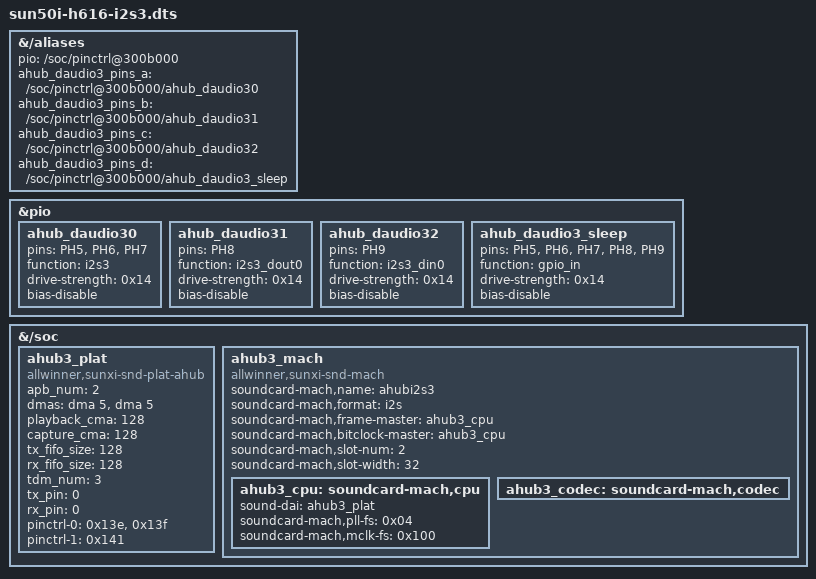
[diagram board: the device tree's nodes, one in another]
/dts-v1/;
/plugin/;

&{/aliases} {
	pio = "/soc/pinctrl@300b000";
	ahub_daudio3_pins_a = "/soc/pinctrl@300b000/ahub_daudio30";
	ahub_daudio3_pins_b = "/soc/pinctrl@300b000/ahub_daudio31";
	ahub_daudio3_pins_c = "/soc/pinctrl@300b000/ahub_daudio32";
	ahub_daudio3_pins_d = "/soc/pinctrl@300b000/ahub_daudio3_sleep";
	};

&pio {
		ahub_daudio30 {
			pins = "PH5", "PH6", "PH7";
			function = "i2s3";
			drive-strength = <0x14>;
			bias-disable;
			phandle = <0xa0>;
						};
		ahub_daudio31 {
			pins = "PH8";
			function = "i2s3_dout0";
			drive-strength = <0x14>;
			bias-disable;
			phandle = <0xa1>;
						};
		ahub_daudio32  {
			pins = "PH9";
			function = "i2s3_din0";
			drive-strength = <0x14>;
			bias-disable;
			phandle = <0xa2>;
						};
		ahub_daudio3_sleep  {
			pins = "PH5", "PH6", "PH7", "PH8", "PH9";
			function = "gpio_in";
			drive-strength = <0x14>;
			bias-disable;
			phandle = <0xa3>;
						};
};

&{/soc}  {
	ahub3_plat: ahub3_plat {
		#sound-dai-cells = <0>;
		compatible	= "allwinner,sunxi-snd-plat-ahub";
		apb_num		= <2>;	/* for dma port 5 */
		dmas		= <&dma 5>, <&dma 5>;
		dma-names	= "tx", "rx";
		playback_cma	= <128>;
		capture_cma	= <128>;
		tx_fifo_size	= <128>;
		rx_fifo_size	= <128>;

		tdm_num		= <3>;
		tx_pin		= <0>;
		rx_pin		= <0>;
		status		= "okay";

		//pinctrl_used;
		pinctrl-names = "default", "sleep";

		pinctrl-0 = <0x13e>, <0x13f>;
		pinctrl-1 = <0x141>;

	//	pinctrl-0 = <0xa0>, <0xa1>;
	//	pinctrl-1 = <0xa3>;

		};
	ahub3_mach: ahub3_mach {
		compatible = "allwinner,sunxi-snd-mach";
		soundcard-mach,name = "ahubi2s3";
		soundcard-mach,format		= "i2s";
		soundcard-mach,frame-master	= <&ahub3_cpu>;
		soundcard-mach,bitclock-master	= <&ahub3_cpu>;
		/* soundcard-mach,frame-inversion; */
		/* soundcard-mach,bitclock-inversion; */
		soundcard-mach,slot-num		= <2>;
		soundcard-mach,slot-width	= <32>;
		status = "okay";
		ahub3_cpu: soundcard-mach,cpu {
			sound-dai = <&ahub3_plat>;
			soundcard-mach,pll-fs	= <0x04>;
			soundcard-mach,mclk-fs	= <0x100>;
						};

			ahub3_codec: soundcard-mach,codec {
							};
				};
};
